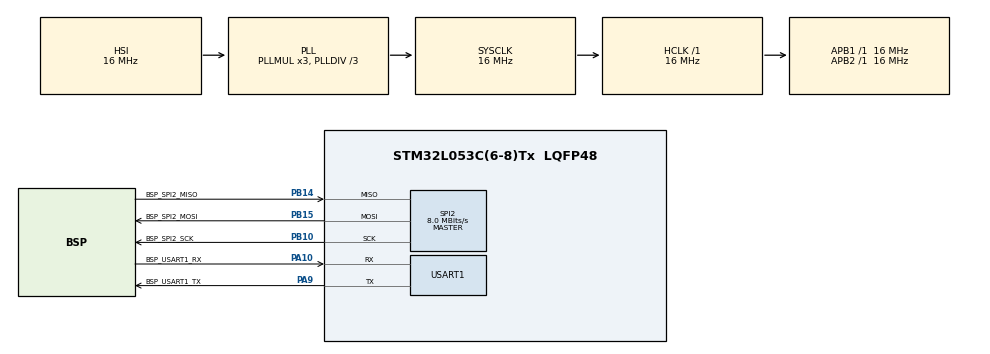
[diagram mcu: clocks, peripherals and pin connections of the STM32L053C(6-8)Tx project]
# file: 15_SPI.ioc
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Dma.Request0=SPI2_RX
Dma.Request1=SPI2_TX
Dma.SPI2_RX.0.Direction=DMA_PERIPH_TO_MEMORY
Dma.SPI2_RX.0.Instance=DMA1_Channel4
Dma.SPI2_RX.0.MemDataAlignment=DMA_MDATAALIGN_BYTE
Dma.SPI2_RX.0.MemInc=DMA_MINC_ENABLE
Dma.SPI2_RX.0.Mode=DMA_NORMAL
Dma.SPI2_RX.0.PeriphDataAlignment=DMA_PDATAALIGN_BYTE
Dma.SPI2_RX.0.PeriphInc=DMA_PINC_DISABLE
Dma.SPI2_RX.0.Priority=DMA_PRIORITY_LOW
Dma.SPI2_TX.1.Direction=DMA_MEMORY_TO_PERIPH
Dma.SPI2_TX.1.Instance=DMA1_Channel5
Dma.SPI2_TX.1.MemDataAlignment=DMA_MDATAALIGN_BYTE
Dma.SPI2_TX.1.MemInc=DMA_MINC_ENABLE
Dma.SPI2_TX.1.Mode=DMA_NORMAL
Dma.SPI2_TX.1.PeriphDataAlignment=DMA_PDATAALIGN_BYTE
Dma.SPI2_TX.1.PeriphInc=DMA_PINC_DISABLE
Dma.SPI2_TX.1.Priority=DMA_PRIORITY_LOW
Mcu.Family=STM32L0
Mcu.Name=STM32L053C(6-8)Tx
Mcu.Package=LQFP48
NVIC.DMA1_Channel4_5_6_7_IRQn=true\:0\:0\:false\:false\:true\:false\:true\:true
NVIC.SPI2_IRQn=true\:0\:0\:false\:false\:true\:true\:true\:true
NVIC.USART1_IRQn=true\:0\:0\:false\:false\:true\:true\:true\:true
PA10.GPIO_Label=BSP_USART1_RX
PA10.Mode=Asynchronous
PA10.Signal=USART1_RX
PA9.GPIO_Label=BSP_USART1_TX
PA9.Mode=Asynchronous
PA9.Signal=USART1_TX
PB10.GPIO_Label=BSP_SPI2_SCK
PB10.Mode=Full_Duplex_Master
PB10.Signal=SPI2_SCK
PB14.GPIO_Label=BSP_SPI2_MISO
PB14.Mode=Full_Duplex_Master
PB14.Signal=SPI2_MISO
PB15.GPIO_Label=BSP_SPI2_MOSI
PB15.Mode=Full_Duplex_Master
PB15.Signal=SPI2_MOSI
ProjectManager.HeapSize=0x200
ProjectManager.StackSize=0x400
ProjectManager.TargetToolchain=STM32CubeIDE
RCC.AHBFreq_Value=16000000
RCC.APB1Freq_Value=16000000
RCC.APB1TimFreq_Value=16000000
RCC.APB2Freq_Value=16000000
RCC.APB2TimFreq_Value=16000000
RCC.HCLKFreq_Value=16000000
RCC.HSE_VALUE=8000000
RCC.HSI16_VALUE=16000000
RCC.HSI48MClockSelection=RCC_USBCLKSOURCE_HSI48
RCC.HSI48_VALUE=48000000
RCC.HSI_VALUE=16000000
RCC.LSE_VALUE=32768
RCC.MSI_VALUE=2097000
RCC.PLLDIV=RCC_PLLDIV_3
RCC.RTCClockSelectionVirtual=RCC_RTCCLKSOURCE_LSE
RCC.SYSCLKFreq_VALUE=16000000
RCC.SYSCLKSource=RCC_SYSCLKSOURCE_PLLCLK
RCC.VCOOutputFreq_Value=48000000
SPI2.CalculateBaudRate=8.0 MBits/s
SPI2.Direction=SPI_DIRECTION_2LINES
SPI2.Mode=SPI_MODE_MASTER
SPI2.VirtualType=VM_MASTER
USART1.VirtualMode-Asynchronous=VM_ASYNC
board=STM32L0538-DISCO

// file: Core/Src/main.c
/* USER CODE BEGIN Header */
/**
  ******************************************************************************
  * @file           : main.c
  * @brief          : Main program body
  ******************************************************************************
  * @attention
  *
  * Copyright (c) 2024 STMicroelectronics.
  * All rights reserved.
  *
  * This software is licensed under terms that can be found in the LICENSE file
  * in the root directory of this software component.
  * If no LICENSE file comes with this software, it is provided AS-IS.
  *
  ******************************************************************************
  */
/* USER CODE END Header */
#include "main.h"
#include "string.h" // Include string.h for memset function

/* USER CODE BEGIN Includes */
#include<stdio.h>
/* USER CODE END Includes */

/* USER CODE BEGIN PD */
#define BUFFER_SIZE 5 // Define the size of the buffer
/* USER CODE END PD */

SPI_HandleTypeDef hspi2;
DMA_HandleTypeDef hdma_spi2_rx;
DMA_HandleTypeDef hdma_spi2_tx;

UART_HandleTypeDef huart1;

/* USER CODE BEGIN PV */

uint8_t tx_data[BUFFER_SIZE] = {8,14,10,2};
uint8_t rx_data[BUFFER_SIZE] = {0};

/* USER CODE END PV */

void SystemClock_Config(void);
static void MX_GPIO_Init(void);
static void MX_DMA_Init(void);
static void MX_SPI2_Init(void);
static void MX_USART1_UART_Init(void);

int main(void)
{

  /* MCU Configuration--------------------------------------------------------*/

  /* Reset of all peripherals, Initializes the Flash interface and the Systick. */
  HAL_Init();

  /* Configure the system clock */
  SystemClock_Config();

  /* Initialize all configured peripherals */
  MX_GPIO_Init();
  MX_DMA_Init();
  MX_SPI2_Init();
  MX_USART1_UART_Init();
  /* USER CODE BEGIN 2 */
  // Clear the buffer before transmitting and receiving data
  memset(rx_data, 0, BUFFER_SIZE);

  HAL_SPI_TransmitReceive_DMA(&hspi2, tx_data, rx_data, sizeof(tx_data));

  /* USER CODE END 2 */

  /* Infinite loop */
    while (1)
  {

    /* USER CODE BEGIN 3 */
//    printf("start\r\n");
//    printf("%s", rx_data);
  }
  /* USER CODE END 3 */
}

void SystemClock_Config(void)
{
  RCC_OscInitTypeDef RCC_OscInitStruct = {0};
  RCC_ClkInitTypeDef RCC_ClkInitStruct = {0};
  RCC_PeriphCLKInitTypeDef PeriphClkInit = {0};

  /** Configure the main internal regulator output voltage
  */
  __HAL_PWR_VOLTAGESCALING_CONFIG(PWR_REGULATOR_VOLTAGE_SCALE1);

  /** Initializes the RCC Oscillators according to the specified parameters
  * in the RCC_OscInitTypeDef structure.
  */
  RCC_OscInitStruct.OscillatorType = RCC_OSCILLATORTYPE_HSI;
  RCC_OscInitStruct.HSIState = RCC_HSI_ON;
  RCC_OscInitStruct.HSICalibrationValue = RCC_HSICALIBRATION_DEFAULT;
  RCC_OscInitStruct.PLL.PLLState = RCC_PLL_ON;
  RCC_OscInitStruct.PLL.PLLSource = RCC_PLLSOURCE_HSI;
  RCC_OscInitStruct.PLL.PLLMUL = RCC_PLLMUL_3;
  RCC_OscInitStruct.PLL.PLLDIV = RCC_PLLDIV_3;
  if (HAL_RCC_OscConfig(&RCC_OscInitStruct) != HAL_OK)
  {
    Error_Handler();
  }

  /** Initializes the CPU, AHB and APB buses clocks
  */
  RCC_ClkInitStruct.ClockType = RCC_CLOCKTYPE_HCLK|RCC_CLOCKTYPE_SYSCLK
                              |RCC_CLOCKTYPE_PCLK1|RCC_CLOCKTYPE_PCLK2;
  RCC_ClkInitStruct.SYSCLKSource = RCC_SYSCLKSOURCE_PLLCLK;
  RCC_ClkInitStruct.AHBCLKDivider = RCC_SYSCLK_DIV1;
  RCC_ClkInitStruct.APB1CLKDivider = RCC_HCLK_DIV1;
  RCC_ClkInitStruct.APB2CLKDivider = RCC_HCLK_DIV1;

  if (HAL_RCC_ClockConfig(&RCC_ClkInitStruct, FLASH_LATENCY_0) != HAL_OK)
  {
    Error_Handler();
  }
  PeriphClkInit.PeriphClockSelection = RCC_PERIPHCLK_USART1;
  PeriphClkInit.Usart1ClockSelection = RCC_USART1CLKSOURCE_PCLK2;
  if (HAL_RCCEx_PeriphCLKConfig(&PeriphClkInit) != HAL_OK)
  {
    Error_Handler();
  }
}

static void MX_SPI2_Init(void)
{

  /* SPI2 parameter configuration*/
  hspi2.Instance = SPI2;
  hspi2.Init.Mode = SPI_MODE_MASTER;
  hspi2.Init.Direction = SPI_DIRECTION_2LINES;
  hspi2.Init.DataSize = SPI_DATASIZE_8BIT;
  hspi2.Init.CLKPolarity = SPI_POLARITY_LOW;
  hspi2.Init.CLKPhase = SPI_PHASE_1EDGE;
  hspi2.Init.NSS = SPI_NSS_SOFT;
  hspi2.Init.BaudRatePrescaler = SPI_BAUDRATEPRESCALER_2;
  hspi2.Init.FirstBit = SPI_FIRSTBIT_MSB;
  hspi2.Init.TIMode = SPI_TIMODE_DISABLE;
  hspi2.Init.CRCCalculation = SPI_CRCCALCULATION_DISABLE;
  hspi2.Init.CRCPolynomial = 7;
  if (HAL_SPI_Init(&hspi2) != HAL_OK)
  {
    Error_Handler();
  }

}

static void MX_USART1_UART_Init(void)
{

  huart1.Instance = USART1;
  huart1.Init.BaudRate = 115200;
  huart1.Init.WordLength = UART_WORDLENGTH_8B;
  huart1.Init.StopBits = UART_STOPBITS_1;
  huart1.Init.Parity = UART_PARITY_NONE;
  huart1.Init.Mode = UART_MODE_TX_RX;
  huart1.Init.HwFlowCtl = UART_HWCONTROL_NONE;
  huart1.Init.OverSampling = UART_OVERSAMPLING_16;
  huart1.Init.OneBitSampling = UART_ONE_BIT_SAMPLE_DISABLE;
  huart1.AdvancedInit.AdvFeatureInit = UART_ADVFEATURE_NO_INIT;
  if (HAL_UART_Init(&huart1) != HAL_OK)
  {
    Error_Handler();
  }

}

static void MX_DMA_Init(void)
{

  /* DMA controller clock enable */
  __HAL_RCC_DMA1_CLK_ENABLE();

  /* DMA interrupt init */
  /* DMA1_Channel4_5_6_7_IRQn interrupt configuration */
  HAL_NVIC_SetPriority(DMA1_Channel4_5_6_7_IRQn, 0, 0);
  HAL_NVIC_EnableIRQ(DMA1_Channel4_5_6_7_IRQn);

}

static void MX_GPIO_Init(void)
{

  /* GPIO Ports Clock Enable */
  __HAL_RCC_GPIOB_CLK_ENABLE();
  __HAL_RCC_GPIOA_CLK_ENABLE();

}

/* USER CODE BEGIN 4 */
void HAL_SPI_TxRxCpltCallback(SPI_HandleTypeDef *hspi)
{
  /* Prevent unused argument(s) compilation warning */
//  UNUSED(hspi);
    HAL_SPI_Transmit_DMA(&hspi2, rx_data, sizeof(rx_data));
    printf("callback function is called\r\n");
    printf("Received data: ");
      for (int i = 0; i < BUFFER_SIZE; i++) {
          printf("%d ", rx_data[i]);
      }
      printf("\r\n");

  /* NOTE : This function should not be modified, when the callback is needed,
            the HAL_SPI_TxRxCpltCallback should be implemented in the user file
   */
}
/* USER CODE END 4 */

void Error_Handler(void)
{
  __disable_irq();
  while (1)
  {
  }
}
